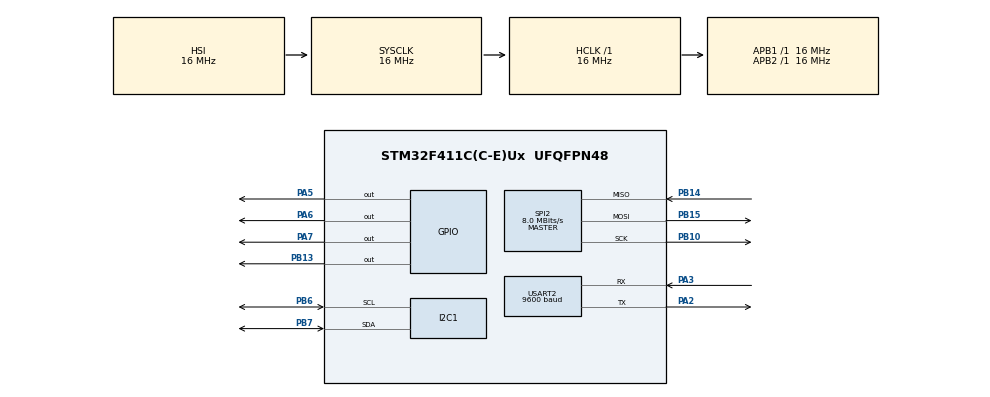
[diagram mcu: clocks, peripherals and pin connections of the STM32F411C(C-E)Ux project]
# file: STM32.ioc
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I2C1.I2C_Mode=I2C_Fast
Mcu.Family=STM32F4
Mcu.Name=STM32F411C(C-E)Ux
Mcu.Package=UFQFPN48
NVIC.PriorityGroup=NVIC_PRIORITYGROUP_4
NVIC.TIM1_UP_TIM10_IRQn=true\:0\:0\:false\:false\:true\:true\:true\:true
NVIC.USART2_IRQn=true\:0\:0\:false\:false\:true\:true\:true\:true
PA2.Mode=Asynchronous
PA2.Signal=USART2_TX
PA3.Mode=Asynchronous
PA3.Signal=USART2_RX
PA5.PinState=GPIO_PIN_SET
PA5.Signal=GPIO_Output
PA6.PinState=GPIO_PIN_SET
PA6.Signal=GPIO_Output
PA7.PinState=GPIO_PIN_SET
PA7.Signal=GPIO_Output
PB10.Mode=Full_Duplex_Master
PB10.Signal=SPI2_SCK
PB13.Signal=GPIO_Output
PB14.Mode=Full_Duplex_Master
PB14.Signal=SPI2_MISO
PB15.Mode=Full_Duplex_Master
PB15.Signal=SPI2_MOSI
PB6.Mode=I2C
PB6.Signal=I2C1_SCL
PB7.Mode=I2C
PB7.Signal=I2C1_SDA
PH0\ -\ OSC_IN.Mode=HSE-External-Oscillator
PH0\ -\ OSC_IN.Signal=RCC_OSC_IN
PH1\ -\ OSC_OUT.Mode=HSE-External-Oscillator
PH1\ -\ OSC_OUT.Signal=RCC_OSC_OUT
ProjectManager.HeapSize=0x200
ProjectManager.StackSize=0x400
ProjectManager.TargetToolchain=STM32CubeIDE
RCC.48MHZClocksFreq_Value=48000000
RCC.AHBFreq_Value=16000000
RCC.APB1Freq_Value=16000000
RCC.APB1TimFreq_Value=16000000
RCC.APB2Freq_Value=16000000
RCC.APB2TimFreq_Value=16000000
RCC.CortexFreq_Value=16000000
RCC.HCLKFreq_Value=16000000
RCC.HSE_VALUE=25000000
RCC.HSI_VALUE=16000000
RCC.LSE_VALUE=32768
RCC.PLLM=15
RCC.PLLN=144
RCC.PLLQ=5
RCC.PLLSourceVirtual=RCC_PLLSOURCE_HSE
RCC.SYSCLKFreq_VALUE=16000000
RCC.VCOOutputFreq_Value=240000000
SPI2.BaudRatePrescaler=SPI_BAUDRATEPRESCALER_2
SPI2.CalculateBaudRate=8.0 MBits/s
SPI2.Direction=SPI_DIRECTION_2LINES
SPI2.Mode=SPI_MODE_MASTER
SPI2.VirtualType=VM_MASTER
TIM1.AutoReloadPreload=TIM_AUTORELOAD_PRELOAD_ENABLE
TIM1.Period=999
TIM1.Prescaler=16
TIM1.TIM_MasterOutputTrigger=TIM_TRGO_UPDATE
TIM1.TIM_MasterSlaveMode=TIM_MASTERSLAVEMODE_DISABLE
USART2.BaudRate=9600
USART2.VirtualMode=VM_ASYNC
VP_TIM1_VS_ClockSourceINT.Mode=Internal
board=custom

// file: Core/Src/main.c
/* USER CODE BEGIN Header */
/**
  ******************************************************************************
  * @file           : main.c
  * @brief          : Main program body
  ******************************************************************************
  * @attention
  *
  * Copyright (c) 2026 STMicroelectronics.
  * All rights reserved.
  *
  * This software is licensed under terms that can be found in the LICENSE file
  * in the root directory of this software component.
  * If no LICENSE file comes with this software, it is provided AS-IS.
  *
  ******************************************************************************
  */
/* USER CODE END Header */
#include "main.h"

/* USER CODE BEGIN Includes */
#include "maincpp.h"
/* USER CODE END Includes */

I2C_HandleTypeDef hi2c1;

SPI_HandleTypeDef hspi2;

TIM_HandleTypeDef htim1;

UART_HandleTypeDef huart2;

void SystemClock_Config(void);
static void MX_GPIO_Init(void);
static void MX_USART2_UART_Init(void);
static void MX_I2C1_Init(void);
static void MX_SPI2_Init(void);
static void MX_TIM1_Init(void);

int main(void)
{

  /* MCU Configuration--------------------------------------------------------*/

  /* Reset of all peripherals, Initializes the Flash interface and the Systick. */
  HAL_Init();

  /* Configure the system clock */
  SystemClock_Config();

  /* Initialize all configured peripherals */
  MX_GPIO_Init();
  MX_USART2_UART_Init();
  MX_I2C1_Init();
  MX_SPI2_Init();
  MX_TIM1_Init();

  /* Infinite loop */
  /* USER CODE BEGIN WHILE */
  setup();
  while (1)
  {
    loop(NULL);
    /* USER CODE END WHILE */

  }
}

void SystemClock_Config(void)
{
  RCC_OscInitTypeDef RCC_OscInitStruct = {0};
  RCC_ClkInitTypeDef RCC_ClkInitStruct = {0};

  /** Configure the main internal regulator output voltage
  */
  __HAL_RCC_PWR_CLK_ENABLE();
  __HAL_PWR_VOLTAGESCALING_CONFIG(PWR_REGULATOR_VOLTAGE_SCALE1);

  /** Initializes the RCC Oscillators according to the specified parameters
  * in the RCC_OscInitTypeDef structure.
  */
  RCC_OscInitStruct.OscillatorType = RCC_OSCILLATORTYPE_HSI;
  RCC_OscInitStruct.HSIState = RCC_HSI_ON;
  RCC_OscInitStruct.HSICalibrationValue = RCC_HSICALIBRATION_DEFAULT;
  RCC_OscInitStruct.PLL.PLLState = RCC_PLL_NONE;
  if (HAL_RCC_OscConfig(&RCC_OscInitStruct) != HAL_OK)
  {
    Error_Handler();
  }

  /** Initializes the CPU, AHB and APB buses clocks
  */
  RCC_ClkInitStruct.ClockType = RCC_CLOCKTYPE_HCLK|RCC_CLOCKTYPE_SYSCLK
                              |RCC_CLOCKTYPE_PCLK1|RCC_CLOCKTYPE_PCLK2;
  RCC_ClkInitStruct.SYSCLKSource = RCC_SYSCLKSOURCE_HSI;
  RCC_ClkInitStruct.AHBCLKDivider = RCC_SYSCLK_DIV1;
  RCC_ClkInitStruct.APB1CLKDivider = RCC_HCLK_DIV1;
  RCC_ClkInitStruct.APB2CLKDivider = RCC_HCLK_DIV1;

  if (HAL_RCC_ClockConfig(&RCC_ClkInitStruct, FLASH_LATENCY_0) != HAL_OK)
  {
    Error_Handler();
  }
}

static void MX_I2C1_Init(void)
{

  hi2c1.Instance = I2C1;
  hi2c1.Init.ClockSpeed = 400000;
  hi2c1.Init.DutyCycle = I2C_DUTYCYCLE_2;
  hi2c1.Init.OwnAddress1 = 0;
  hi2c1.Init.AddressingMode = I2C_ADDRESSINGMODE_7BIT;
  hi2c1.Init.DualAddressMode = I2C_DUALADDRESS_DISABLE;
  hi2c1.Init.OwnAddress2 = 0;
  hi2c1.Init.GeneralCallMode = I2C_GENERALCALL_DISABLE;
  hi2c1.Init.NoStretchMode = I2C_NOSTRETCH_DISABLE;
  if (HAL_I2C_Init(&hi2c1) != HAL_OK)
  {
    Error_Handler();
  }

}

static void MX_SPI2_Init(void)
{

  /* SPI2 parameter configuration*/
  hspi2.Instance = SPI2;
  hspi2.Init.Mode = SPI_MODE_MASTER;
  hspi2.Init.Direction = SPI_DIRECTION_2LINES;
  hspi2.Init.DataSize = SPI_DATASIZE_8BIT;
  hspi2.Init.CLKPolarity = SPI_POLARITY_LOW;
  hspi2.Init.CLKPhase = SPI_PHASE_1EDGE;
  hspi2.Init.NSS = SPI_NSS_SOFT;
  hspi2.Init.BaudRatePrescaler = SPI_BAUDRATEPRESCALER_2;
  hspi2.Init.FirstBit = SPI_FIRSTBIT_MSB;
  hspi2.Init.TIMode = SPI_TIMODE_DISABLE;
  hspi2.Init.CRCCalculation = SPI_CRCCALCULATION_DISABLE;
  hspi2.Init.CRCPolynomial = 10;
  if (HAL_SPI_Init(&hspi2) != HAL_OK)
  {
    Error_Handler();
  }

}

static void MX_TIM1_Init(void)
{

  TIM_ClockConfigTypeDef sClockSourceConfig = {0};
  TIM_MasterConfigTypeDef sMasterConfig = {0};

  htim1.Instance = TIM1;
  htim1.Init.Prescaler = 16;
  htim1.Init.CounterMode = TIM_COUNTERMODE_UP;
  htim1.Init.Period = 999;
  htim1.Init.ClockDivision = TIM_CLOCKDIVISION_DIV1;
  htim1.Init.RepetitionCounter = 0;
  htim1.Init.AutoReloadPreload = TIM_AUTORELOAD_PRELOAD_ENABLE;
  if (HAL_TIM_Base_Init(&htim1) != HAL_OK)
  {
    Error_Handler();
  }
  sClockSourceConfig.ClockSource = TIM_CLOCKSOURCE_INTERNAL;
  if (HAL_TIM_ConfigClockSource(&htim1, &sClockSourceConfig) != HAL_OK)
  {
    Error_Handler();
  }
  sMasterConfig.MasterOutputTrigger = TIM_TRGO_UPDATE;
  sMasterConfig.MasterSlaveMode = TIM_MASTERSLAVEMODE_DISABLE;
  if (HAL_TIMEx_MasterConfigSynchronization(&htim1, &sMasterConfig) != HAL_OK)
  {
    Error_Handler();
  }

}

static void MX_USART2_UART_Init(void)
{

  huart2.Instance = USART2;
  huart2.Init.BaudRate = 9600;
  huart2.Init.WordLength = UART_WORDLENGTH_8B;
  huart2.Init.StopBits = UART_STOPBITS_1;
  huart2.Init.Parity = UART_PARITY_NONE;
  huart2.Init.Mode = UART_MODE_TX_RX;
  huart2.Init.HwFlowCtl = UART_HWCONTROL_NONE;
  huart2.Init.OverSampling = UART_OVERSAMPLING_16;
  if (HAL_UART_Init(&huart2) != HAL_OK)
  {
    Error_Handler();
  }

}

static void MX_GPIO_Init(void)
{
  GPIO_InitTypeDef GPIO_InitStruct = {0};

  /* GPIO Ports Clock Enable */
  __HAL_RCC_GPIOH_CLK_ENABLE();
  __HAL_RCC_GPIOA_CLK_ENABLE();
  __HAL_RCC_GPIOB_CLK_ENABLE();

  /*Configure GPIO pin Output Level */
  HAL_GPIO_WritePin(GPIOA, GPIO_PIN_5|GPIO_PIN_6|GPIO_PIN_7, GPIO_PIN_SET);

  /*Configure GPIO pin Output Level */
  HAL_GPIO_WritePin(GPIOB, GPIO_PIN_13, GPIO_PIN_RESET);

  /*Configure GPIO pins : PA5 PA6 PA7 */
  GPIO_InitStruct.Pin = GPIO_PIN_5|GPIO_PIN_6|GPIO_PIN_7;
  GPIO_InitStruct.Mode = GPIO_MODE_OUTPUT_PP;
  GPIO_InitStruct.Pull = GPIO_NOPULL;
  GPIO_InitStruct.Speed = GPIO_SPEED_FREQ_LOW;
  HAL_GPIO_Init(GPIOA, &GPIO_InitStruct);

  /*Configure GPIO pin : PB13 */
  GPIO_InitStruct.Pin = GPIO_PIN_13;
  GPIO_InitStruct.Mode = GPIO_MODE_OUTPUT_PP;
  GPIO_InitStruct.Pull = GPIO_NOPULL;
  GPIO_InitStruct.Speed = GPIO_SPEED_FREQ_LOW;
  HAL_GPIO_Init(GPIOB, &GPIO_InitStruct);

}

void Error_Handler(void)
{
  __disable_irq();
  while (1)
  {
  }
}
